# PIC32CX1025SG41080 register map
Vendor: Microchip Technology; Series: PIC32CXSG41; File version: 0
CPU: CM4 r0p1, little endian, MPU, FPU, 3 interrupt priority bits, 137 interrupts
Registers are 32-bit, read-write, reset 0x0 unless marked. A register's access mark holds for its fields unless they carry their own. Offsets are from the block's base; [hi:lo] are bit positions; {n}, {i} and the like mark numbered series; 'fields as' and 'values as' point back to an identical list.

## AC — Analog Comparators
Base 0x42002000
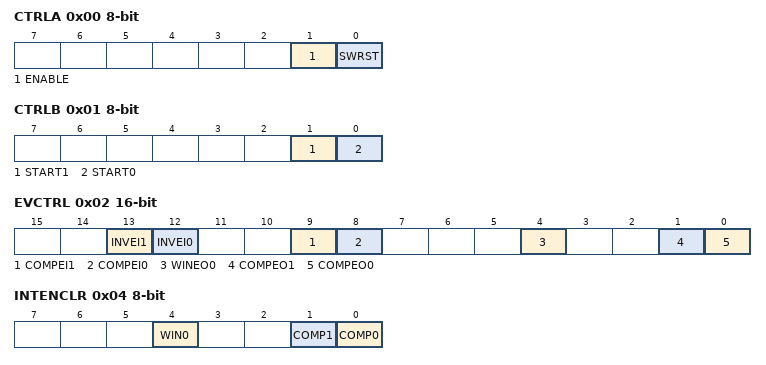
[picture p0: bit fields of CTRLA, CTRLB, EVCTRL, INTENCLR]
0x00 CTRLA 8-bit — Control A
  [1] ENABLE
  [0] SWRST — Software Reset
0x01 CTRLB 8-bit wo — Control B
  [1] START1 — Comparator 1 Start Comparison
  [0] START0 — Comparator 0 Start Comparison
0x02 EVCTRL 16-bit — Event Control
  [13] INVEI1 — Comparator 1 Input Event Invert Enable
  [12] INVEI0 — Comparator 0 Input Event Invert Enable
  [9] COMPEI1 — Comparator 1 Event Input Enable
  [8] COMPEI0 — Comparator 0 Event Input Enable
  [4] WINEO0 — Window 0 Event Output Enable
  [1] COMPEO1 — Comparator 1 Event Output Enable
  [0] COMPEO0 — Comparator 0 Event Output Enable
0x04 INTENCLR 8-bit write-1-clears — Interrupt Enable Clear
  [4] WIN0 — Window 0 Interrupt Enable
  [1] COMP1 — Comparator 1 Interrupt Enable
  [0] COMP0 — Comparator 0 Interrupt Enable
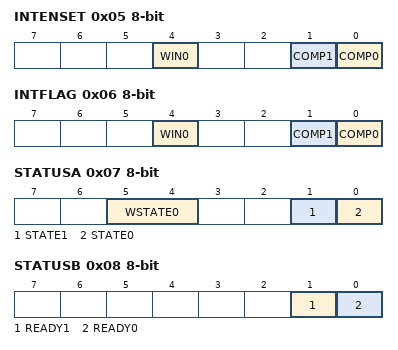
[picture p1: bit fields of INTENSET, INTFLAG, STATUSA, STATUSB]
0x05 INTENSET 8-bit write-1-sets — Interrupt Enable Set
  fields as INTENCLR
0x06 INTFLAG 8-bit write-1-clears — Interrupt Flag Status and Clear
  [4] WIN0 — Window 0
  [1] COMP1 — Comparator 1
  [0] COMP0 — Comparator 0
0x07 STATUSA 8-bit ro
  [5:4] WSTATE0 — Window 0 Current State
    0=ABOVE (Signal is above window); 1=INSIDE (Signal is inside window); 2=BELOW (Signal is below window)
  [1] STATE1 — Comparator 1 Current State
  [0] STATE0 — Comparator 0 Current State
0x08 STATUSB 8-bit ro
  [1] READY1 — Comparator 1 Ready
  [0] READY0 — Comparator 0 Ready
0x09 DBGCTRL 8-bit — Debug Control
  [0] DBGRUN — Debug Run
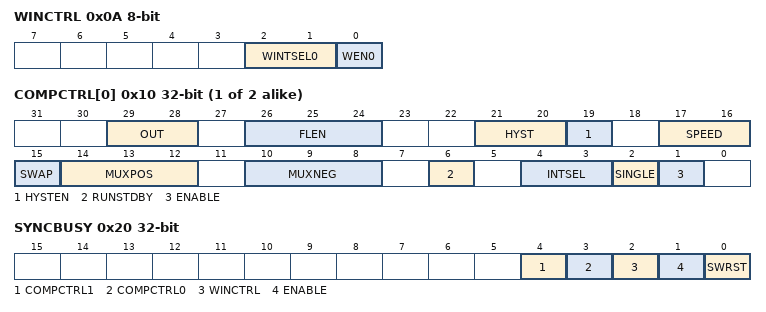
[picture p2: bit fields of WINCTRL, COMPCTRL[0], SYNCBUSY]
0x0A WINCTRL 8-bit — Window Control
  [2:1] WINTSEL0 — Window 0 Interrupt Selection
    0=ABOVE (Interrupt on signal above window); 1=INSIDE (Interrupt on signal inside window); 2=BELOW (Interrupt on signal below window); 3=OUTSIDE (Interrupt on signal outside window)
  [0] WEN0 — Window 0 Mode Enable
{0xC+i} SCALER[{i}] (i=0..1) 8-bit — Scaler n
  [5:0] VALUE — Scaler Value
{0x10+4i} COMPCTRL[{i}] (i=0..1) — Comparator Control n
  [29:28] OUT — Output
    0=OFF (The output of COMPn is not routed to the COMPn I/O port); 1=ASYNC (The asynchronous output of COMPn is routed to the COMPn I/O port); 2=SYNC (The synchronous output (including filtering) of COMPn is routed to the COMPn I/O port)
  [26:24] FLEN — Filter Length
    0=OFF (No filtering); 1=MAJ3 (3-bit majority function (2 of 3)); 2=MAJ5 (5-bit majority function (3 of 5))
  [21:20] HYST — Hysteresis Level
    0=25mV; 1=50mV; 2=75mV; 3=100mV
  [19] HYSTEN — Hysteresis Enable
  [17:16] SPEED — Speed Selection
    0=LOW (Low Power); 3=HIGH (High speed)
  [15] SWAP — Swap Inputs and Invert
  [14:12] MUXPOS — Positive Input Mux Selection
    {v}=PIN{v} (I/O pin {v}) (v=0..3); 4=VSCALE (AVDD scaler)
  [10:8] MUXNEG — Negative Input Mux Selection
    {v}=PIN{v} (I/O pin {v}) (v=0..3); 4=AVSS (Ground); 5=VSCALE (AVDD scaler); 6=BANDGAP (Internal bandgap voltage); 7=DAC0 (DAC0 output)
  [6] RUNSTDBY — Run in Standby
  [4:3] INTSEL — Interrupt Selection
    0=TOGGLE (Interrupt on comparator output toggle); 1=RISING (Interrupt on comparator output rising); 2=FALLING (Interrupt on comparator output falling); 3=EOC (Interrupt on end of comparison (single-shot mode only))
  [2] SINGLE — Single-Shot Mode
  [1] ENABLE
0x20 SYNCBUSY ro — Synchronization Busy
  [4] COMPCTRL1 — COMPCTRL 1 Synchronization Busy
  [3] COMPCTRL0 — COMPCTRL 0 Synchronization Busy
  [2] WINCTRL — WINCTRL Synchronization Busy
  [1] ENABLE — Enable Synchronization Busy
  [0] SWRST — Software Reset Synchronization Busy
0x24 CALIB 16-bit reset 0x101 — Calibration
  [1:0] BIAS0 — COMP0/1 Bias Scaling

## AES — Advanced Encryption Standard
Base 0x42002400
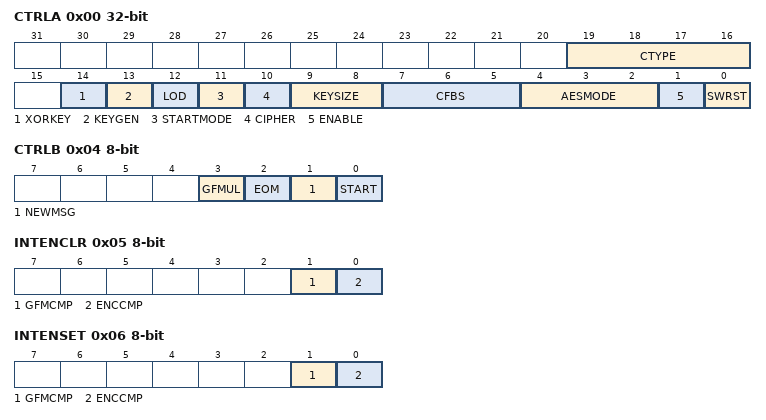
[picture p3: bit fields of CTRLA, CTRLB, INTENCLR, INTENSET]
0x00 CTRLA — Control A
  [19:16] CTYPE — Counter Measure Type
  [14] XORKEY — XOR Key Operation
    0=NONE (No effect); 1=XOR (The user keyword gets XORed with the previous keyword register content.)
  [13] KEYGEN — Last Key Generation
    0=NONE (No effect); 1=LAST (Start Computation of the last NK words of the expanded key)
  [12] LOD — Last Output Data Mode
    0=NONE (No effect); 1=LAST (Start encryption in Last Output Data mode)
  [11] STARTMODE — Start Mode Select
    0=MANUAL (Start Encryption / Decryption in Manual mode); 1=AUTO (Start Encryption / Decryption in Auto mode)
  [10] CIPHER — Cipher Mode
    0=DEC (Decryption); 1=ENC (Encryption)
  [9:8] KEYSIZE — Encryption Key Size
    0=128BIT (128-bit Key for Encryption / Decryption); 1=192BIT (192-bit Key for Encryption / Decryption); 2=256BIT (256-bit Key for Encryption / Decryption)
  [7:5] CFBS — Cipher Feedback Block Size
    0=128BIT (128-bit Input data block for Encryption/Decryption in Cipher Feedback mode); 1=64BIT (64-bit Input data block for Encryption/Decryption in Cipher Feedback mode); 2=32BIT (32-bit Input data block for Encryption/Decryption in Cipher Feedback mode); 3=16BIT (16-bit Input data block for Encryption/Decryption in Cipher Feedback mode); 4=8BIT (8-bit Input data block for Encryption/Decryption in Cipher Feedback mode)
  [4:2] AESMODE — AES Modes of operation
    0=ECB (Electronic code book mode); 1=CBC (Cipher block chaining mode); 2=OFB (Output feedback mode); 3=CFB (Cipher feedback mode); 4=COUNTER (Counter mode); 5=CCM (CCM mode); 6=GCM (Galois counter mode)
  [1] ENABLE
  [0] SWRST — Software Reset
0x04 CTRLB 8-bit — Control B
  [3] GFMUL — GF Multiplication
  [2] EOM — End of message
  [1] NEWMSG — New message
  [0] START — Start Encryption/Decryption
0x05 INTENCLR 8-bit write-1-clears — Interrupt Enable Clear
  [1] GFMCMP — GF Multiplication Complete Interrupt Enable
  [0] ENCCMP — Encryption Complete Interrupt Enable
0x06 INTENSET 8-bit write-1-sets — Interrupt Enable Set
  fields as INTENCLR
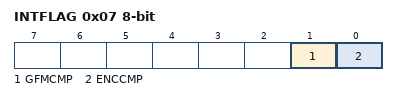
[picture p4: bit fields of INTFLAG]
0x07 INTFLAG 8-bit write-1-clears — Interrupt Flag Status
  [1] GFMCMP — GF Multiplication Complete
  [0] ENCCMP — Encryption Complete
0x08 DATABUFPTR 8-bit — Data buffer pointer
  [1:0] INDATAPTR — Input Data Pointer
0x09 DBGCTRL 8-bit — Debug control
  [0] DBGRUN — Debug Run
{0xC+4i} KEYWORD[{i}] (i=0..7) wo — Keyword n
  [31:0] KEYWORD — Key Word Value
0x38 INDATA
  [31:0] INDATA — Data Value
{0x3C+4i} INTVECTV[{i}] (i=0..3) wo — Initialisation Vector n
  [31:0] INTVECTV — Initialization Vector Value
{0x5C+4i} HASHKEY[{i}] (i=0..3) — Hash key n
  [31:0] HASHKEY — Hash Key Value
{0x6C+4i} GHASH[{i}] (i=0..3) — Galois Hash n
  [31:0] GHASH — Galois Hash Value
0x80 CIPLEN — Cipher Length
0x84 RANDSEED — Random Seed

## Notices in the file
Copyright (c) 2026 Microchip Technology Inc.
SPDX-License-Identifier: Apache-2.0
Licensed under the Apache License, Version 2.0 (the "License");
you may not use this file except in compliance with the License.
You may obtain a copy of the License at
http://www.apache.org/licenses/LICENSE-2.0
Unless required by applicable law or agreed to in writing, software
distributed under the License is distributed on an "AS IS" BASIS,
WITHOUT WARRANTIES OR CONDITIONS OF ANY KIND, either express or implied.
See the License for the specific language governing permissions and
limitations under the License.
